AUTOSAR XML (schema 4-3-0)
standard types defined: uint8, uint16, uint32, float32, boolean
package /ApplicationSoftwareComponents
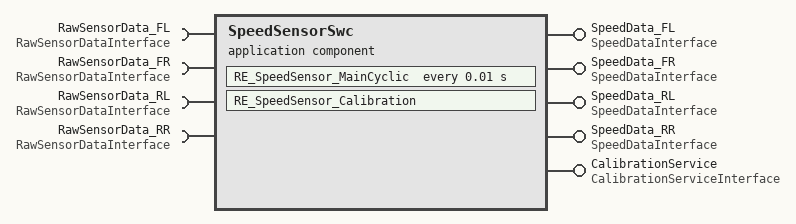
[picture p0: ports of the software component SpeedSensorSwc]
  application sw component type SpeedSensorSwc  # Speed Sensor Software Component | Software component for speed sensor data processing and validation
    4 x provide port, all with provided-interface=SpeedDataInterface:
      SpeedData_FL
      SpeedData_FR
      SpeedData_RL
      SpeedData_RR
    4 x require port, all with required-interface=RawSensorDataInterface:
      RawSensorData_FL
      RawSensorData_FR
      RawSensorData_RL
      RawSensorData_RR
    provide port CalibrationService: provided-interface=CalibrationServiceInterface
    behavior SpeedSensorSwcInternalBehavior
      runnable RE_SpeedSensor_MainCyclic: minimum-start-interval=0.01
        data-read-access:
          access Read_RawSensorData_FL: accessed-variable=RawSensorData_FL.rawData
        data-write-access:
          access Write_SpeedData_FL: accessed-variable=SpeedData_FL.speedData
      runnable RE_SpeedSensor_Calibration
      timing event TE_SpeedSensor_MainCyclic: start-on-event=RE_SpeedSensor_MainCyclic, period=0.01
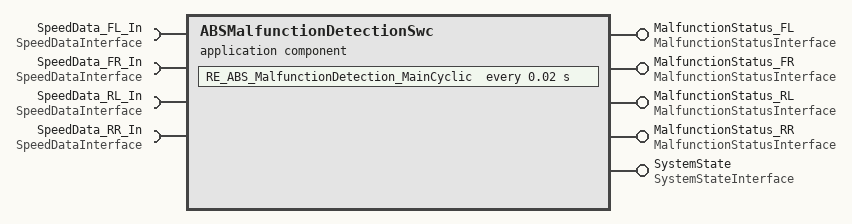
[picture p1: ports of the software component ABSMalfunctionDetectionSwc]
  application sw component type ABSMalfunctionDetectionSwc  # ABS Malfunction Detection Software Component | Software component for detecting ABS malfunctions from miscalibrated speed sensors
    4 x require port, all with required-interface=SpeedDataInterface:
      SpeedData_FL_In
      SpeedData_FR_In
      SpeedData_RL_In
      SpeedData_RR_In
    5 x provide port:
      MalfunctionStatus_FL: provided-interface=MalfunctionStatusInterface
      MalfunctionStatus_FR: provided-interface=MalfunctionStatusInterface
      MalfunctionStatus_RL: provided-interface=MalfunctionStatusInterface
      MalfunctionStatus_RR: provided-interface=MalfunctionStatusInterface
      SystemState: provided-interface=SystemStateInterface
    behavior ABSMalfunctionDetectionSwcInternalBehavior
      runnable RE_ABS_MalfunctionDetection_MainCyclic: minimum-start-interval=0.02
      timing event TE_ABS_MalfunctionDetection_MainCyclic: start-on-event=RE_ABS_MalfunctionDetection_MainCyclic, period=0.02
package /Interfaces
  4 x sender receiver interface:
    SpeedDataInterface
      data speedData: type=SpeedData_t
    RawSensorDataInterface
      data rawData: type=SpeedSensorRawData_t
    MalfunctionStatusInterface
      data status: type=ABS_MalfunctionStatus_t
    SystemStateInterface
      data state: type=ABS_SystemState_t
  client server interface CalibrationServiceInterface
    operation SetCalibration: possible-error=E_NOT_OK
      arg wheelPos: type=WheelPosition_t, direction=IN
      arg calibration: type=SpeedSensorCalibration_t, direction=IN
    operation GetCalibration: possible-error=E_NOT_OK
      arg wheelPos: type=WheelPosition_t, direction=IN
      arg calibration: type=SpeedSensorCalibration_t, direction=OUT
    error E_NOT_OK: error-code=1
package /DataTypes
  6 x impl type:
    WheelPosition_t: category=TYPE_REFERENCE, base-type-encoding=NONE
    ABS_SystemState_t: category=TYPE_REFERENCE, base-type-encoding=NONE
    SpeedData_t: category=STRUCTURE
      5 x element, all with category=TYPE_REFERENCE:
        wheelSpeed: implementation-data-type=float32
        wheelSpeedRaw: implementation-data-type=float32
        accelerationX: implementation-data-type=float32
        speedValid: implementation-data-type=boolean
        qualityFactor: implementation-data-type=uint8
    SpeedSensorRawData_t: category=STRUCTURE
      element pulseCount: implementation-data-type=uint16
      element timeInterval: implementation-data-type=uint16
      element dataValid: implementation-data-type=boolean
    SpeedSensorCalibration_t: category=STRUCTURE
      element correctionFactor: implementation-data-type=float32
      element offsetValue: implementation-data-type=float32
      element calibrationValid: implementation-data-type=boolean
    ABS_MalfunctionStatus_t: category=STRUCTURE
      element isActive: implementation-data-type=boolean
      element affectedWheel: implementation-data-type=WheelPosition_t
      element deviationValue: implementation-data-type=float32
